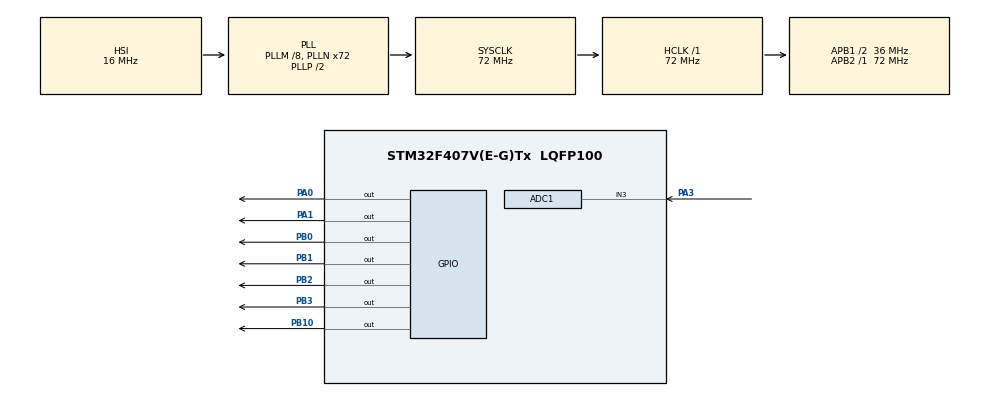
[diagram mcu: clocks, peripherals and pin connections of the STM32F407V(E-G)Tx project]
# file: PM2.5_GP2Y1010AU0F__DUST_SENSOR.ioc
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ADC1.Channel-4\#ChannelRegularConversion=ADC_CHANNEL_3
ADC1.ContinuousConvMode=ENABLE
ADC1.NbrOfConversionFlag=1
ADC1.Rank-4\#ChannelRegularConversion=1
ADC1.SamplingTime-4\#ChannelRegularConversion=ADC_SAMPLETIME_3CYCLES
ADC1.master=1
Mcu.Family=STM32F4
Mcu.Name=STM32F407V(E-G)Tx
Mcu.Package=LQFP100
NVIC.PriorityGroup=NVIC_PRIORITYGROUP_4
PA0-WKUP.Signal=GPIO_Output
PA1.Signal=GPIO_Output
PA13.Mode=Serial_Wire
PA13.Signal=SYS_JTMS-SWDIO
PA14.Mode=Serial_Wire
PA14.Signal=SYS_JTCK-SWCLK
PA3.Signal=ADCx_IN3
PB0.Signal=GPIO_Output
PB1.Signal=GPIO_Output
PB10.Signal=GPIO_Output
PB2.Signal=GPIO_Output
PB3.Signal=GPIO_Output
PH0-OSC_IN.Mode=HSE-External-Oscillator
PH0-OSC_IN.Signal=RCC_OSC_IN
PH1-OSC_OUT.Mode=HSE-External-Oscillator
PH1-OSC_OUT.Signal=RCC_OSC_OUT
ProjectManager.HeapSize=0x200
ProjectManager.StackSize=0x400
ProjectManager.TargetToolchain=STM32CubeIDE
RCC.48MHZClocksFreq_Value=36000000
RCC.AHBFreq_Value=72000000
RCC.APB1CLKDivider=RCC_HCLK_DIV2
RCC.APB1Freq_Value=36000000
RCC.APB1TimFreq_Value=72000000
RCC.APB2Freq_Value=72000000
RCC.APB2TimFreq_Value=72000000
RCC.CortexFreq_Value=72000000
RCC.HCLKFreq_Value=72000000
RCC.HSE_VALUE=25000000
RCC.HSI_VALUE=16000000
RCC.LSE_VALUE=32768
RCC.PLLM=8
RCC.PLLN=72
RCC.SYSCLKFreq_VALUE=72000000
RCC.SYSCLKSource=RCC_SYSCLKSOURCE_PLLCLK
RCC.VCOOutputFreq_Value=144000000
SH.ADCx_IN3.0=ADC1_IN3,IN3
TIM2.Period=0xffff-1
TIM2.Prescaler=72-1
VP_TIM2_VS_ClockSourceINT.Mode=Internal
board=custom

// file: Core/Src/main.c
/* USER CODE BEGIN Header */
/**
  ******************************************************************************
  * @file           : main.c
  * @brief          : Main program body
  ******************************************************************************
  * @attention
  *
  * Copyright (c) 2024 STMicroelectronics.
  * All rights reserved.
  *
  * This software is licensed under terms that can be found in the LICENSE file
  * in the root directory of this software component.
  * If no LICENSE file comes with this software, it is provided AS-IS.
  *
  ******************************************************************************
  */
/* USER CODE END Header */
#include "main.h"

#define sensorLED_PIN GPIO_PIN_10
#define sensorLED_PORT GPIOB

ADC_HandleTypeDef hadc1;

TIM_HandleTypeDef htim2;

void SystemClock_Config(void);
static void MX_GPIO_Init(void);
static void MX_ADC1_Init(void);
static void MX_TIM2_Init(void);

/* USER CODE BEGIN 0 */
void delay_us (uint16_t us)
{
	__HAL_TIM_SET_COUNTER(&htim2,0);  // set the counter value a 0
	while (__HAL_TIM_GET_COUNTER(&htim2) < us);  // wait for the counter to reach the us input in the parameter
}
/* USER CODE END 0 */

int main(void)
{

  /* USER CODE BEGIN 1 */
	float voMeasured = 0;
	float calcVoltage = 0;
	float dustDensity = 0;
  /* USER CODE END 1 */

  /* MCU Configuration--------------------------------------------------------*/

  /* Reset of all peripherals, Initializes the Flash interface and the Systick. */
  HAL_Init();

  /* Configure the system clock */
  SystemClock_Config();

  /* Initialize all configured peripherals */
  MX_GPIO_Init();
  MX_ADC1_Init();
  MX_TIM2_Init();
  HAL_TIM_Base_Start(&htim2);
  HAL_ADC_Start(&hadc1);
  /* Infinite loop */
  while (1)
  {
	  HAL_GPIO_WritePin (sensorLED_PORT, sensorLED_PIN, GPIO_PIN_SET);         //TURN ON SENSOR LED
	  delay_us(280);          // wait for 280us (0.28ms)

	  HAL_ADC_PollForConversion(&hadc1,1000);
	  voMeasured = HAL_ADC_GetValue(&hadc1);       // read ADC value from PA3

	  delay_us(40);
	  HAL_GPIO_WritePin (sensorLED_PORT, sensorLED_PIN, GPIO_PIN_RESET);         //TURN OFF LED
	  delay_us(9680);

	  calcVoltage = voMeasured * (5.0 / 1024.0);
	  dustDensity = 170 * calcVoltage - 0.1;

	  HAL_Delay(1000);
  }
}

void SystemClock_Config(void)
{
  RCC_OscInitTypeDef RCC_OscInitStruct = {0};
  RCC_ClkInitTypeDef RCC_ClkInitStruct = {0};

  /** Configure the main internal regulator output voltage
  */
  __HAL_RCC_PWR_CLK_ENABLE();
  __HAL_PWR_VOLTAGESCALING_CONFIG(PWR_REGULATOR_VOLTAGE_SCALE1);

  /** Initializes the RCC Oscillators according to the specified parameters
  * in the RCC_OscInitTypeDef structure.
  */
  RCC_OscInitStruct.OscillatorType = RCC_OSCILLATORTYPE_HSI;
  RCC_OscInitStruct.HSIState = RCC_HSI_ON;
  RCC_OscInitStruct.HSICalibrationValue = RCC_HSICALIBRATION_DEFAULT;
  RCC_OscInitStruct.PLL.PLLState = RCC_PLL_ON;
  RCC_OscInitStruct.PLL.PLLSource = RCC_PLLSOURCE_HSI;
  RCC_OscInitStruct.PLL.PLLM = 8;
  RCC_OscInitStruct.PLL.PLLN = 72;
  RCC_OscInitStruct.PLL.PLLP = RCC_PLLP_DIV2;
  RCC_OscInitStruct.PLL.PLLQ = 4;
  if (HAL_RCC_OscConfig(&RCC_OscInitStruct) != HAL_OK)
  {
    Error_Handler();
  }

  /** Initializes the CPU, AHB and APB buses clocks
  */
  RCC_ClkInitStruct.ClockType = RCC_CLOCKTYPE_HCLK|RCC_CLOCKTYPE_SYSCLK
                              |RCC_CLOCKTYPE_PCLK1|RCC_CLOCKTYPE_PCLK2;
  RCC_ClkInitStruct.SYSCLKSource = RCC_SYSCLKSOURCE_PLLCLK;
  RCC_ClkInitStruct.AHBCLKDivider = RCC_SYSCLK_DIV1;
  RCC_ClkInitStruct.APB1CLKDivider = RCC_HCLK_DIV2;
  RCC_ClkInitStruct.APB2CLKDivider = RCC_HCLK_DIV1;

  if (HAL_RCC_ClockConfig(&RCC_ClkInitStruct, FLASH_LATENCY_2) != HAL_OK)
  {
    Error_Handler();
  }
}

static void MX_ADC1_Init(void)
{

  ADC_ChannelConfTypeDef sConfig = {0};

  /** Configure the global features of the ADC (Clock, Resolution, Data Alignment and number of conversion)
  */
  hadc1.Instance = ADC1;
  hadc1.Init.ClockPrescaler = ADC_CLOCK_SYNC_PCLK_DIV2;
  hadc1.Init.Resolution = ADC_RESOLUTION_12B;
  hadc1.Init.ScanConvMode = DISABLE;
  hadc1.Init.ContinuousConvMode = ENABLE;
  hadc1.Init.DiscontinuousConvMode = DISABLE;
  hadc1.Init.ExternalTrigConvEdge = ADC_EXTERNALTRIGCONVEDGE_NONE;
  hadc1.Init.ExternalTrigConv = ADC_SOFTWARE_START;
  hadc1.Init.DataAlign = ADC_DATAALIGN_RIGHT;
  hadc1.Init.NbrOfConversion = 1;
  hadc1.Init.DMAContinuousRequests = DISABLE;
  hadc1.Init.EOCSelection = ADC_EOC_SINGLE_CONV;
  if (HAL_ADC_Init(&hadc1) != HAL_OK)
  {
    Error_Handler();
  }

  /** Configure for the selected ADC regular channel its corresponding rank in the sequencer and its sample time.
  */
  sConfig.Channel = ADC_CHANNEL_3;
  sConfig.Rank = 1;
  sConfig.SamplingTime = ADC_SAMPLETIME_3CYCLES;
  if (HAL_ADC_ConfigChannel(&hadc1, &sConfig) != HAL_OK)
  {
    Error_Handler();
  }

}

static void MX_TIM2_Init(void)
{

  TIM_ClockConfigTypeDef sClockSourceConfig = {0};
  TIM_MasterConfigTypeDef sMasterConfig = {0};

  htim2.Instance = TIM2;
  htim2.Init.Prescaler = 72-1;
  htim2.Init.CounterMode = TIM_COUNTERMODE_UP;
  htim2.Init.Period = 0xffff-1;
  htim2.Init.ClockDivision = TIM_CLOCKDIVISION_DIV1;
  htim2.Init.AutoReloadPreload = TIM_AUTORELOAD_PRELOAD_DISABLE;
  if (HAL_TIM_Base_Init(&htim2) != HAL_OK)
  {
    Error_Handler();
  }
  sClockSourceConfig.ClockSource = TIM_CLOCKSOURCE_INTERNAL;
  if (HAL_TIM_ConfigClockSource(&htim2, &sClockSourceConfig) != HAL_OK)
  {
    Error_Handler();
  }
  sMasterConfig.MasterOutputTrigger = TIM_TRGO_RESET;
  sMasterConfig.MasterSlaveMode = TIM_MASTERSLAVEMODE_DISABLE;
  if (HAL_TIMEx_MasterConfigSynchronization(&htim2, &sMasterConfig) != HAL_OK)
  {
    Error_Handler();
  }

}

static void MX_GPIO_Init(void)
{
  GPIO_InitTypeDef GPIO_InitStruct = {0};

  /* GPIO Ports Clock Enable */
  __HAL_RCC_GPIOH_CLK_ENABLE();
  __HAL_RCC_GPIOA_CLK_ENABLE();
  __HAL_RCC_GPIOB_CLK_ENABLE();

  /*Configure GPIO pin Output Level */
  HAL_GPIO_WritePin(GPIOA, GPIO_PIN_0|GPIO_PIN_1, GPIO_PIN_RESET);

  /*Configure GPIO pin Output Level */
  HAL_GPIO_WritePin(GPIOB, GPIO_PIN_0|GPIO_PIN_1|GPIO_PIN_2|GPIO_PIN_10
                          |GPIO_PIN_3, GPIO_PIN_RESET);

  /*Configure GPIO pins : PA0 PA1 */
  GPIO_InitStruct.Pin = GPIO_PIN_0|GPIO_PIN_1;
  GPIO_InitStruct.Mode = GPIO_MODE_OUTPUT_PP;
  GPIO_InitStruct.Pull = GPIO_NOPULL;
  GPIO_InitStruct.Speed = GPIO_SPEED_FREQ_LOW;
  HAL_GPIO_Init(GPIOA, &GPIO_InitStruct);

  /*Configure GPIO pins : PB0 PB1 PB2 PB10
                           PB3 */
  GPIO_InitStruct.Pin = GPIO_PIN_0|GPIO_PIN_1|GPIO_PIN_2|GPIO_PIN_10
                          |GPIO_PIN_3;
  GPIO_InitStruct.Mode = GPIO_MODE_OUTPUT_PP;
  GPIO_InitStruct.Pull = GPIO_NOPULL;
  GPIO_InitStruct.Speed = GPIO_SPEED_FREQ_LOW;
  HAL_GPIO_Init(GPIOB, &GPIO_InitStruct);

}

void Error_Handler(void)
{
  __disable_irq();
  while (1)
  {
  }
}
